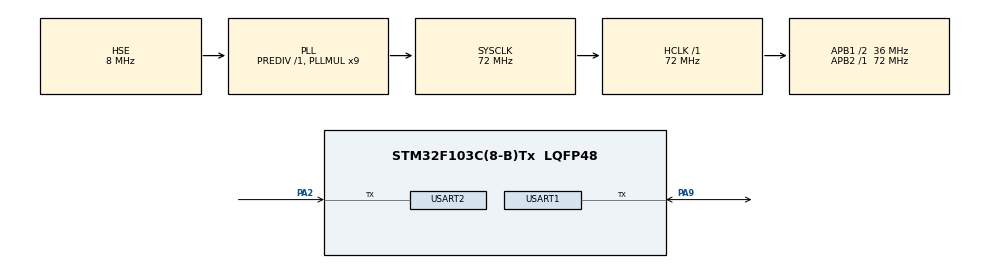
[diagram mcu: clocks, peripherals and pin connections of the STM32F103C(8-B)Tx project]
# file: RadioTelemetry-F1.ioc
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Dma.Request0=USART1_RX
Dma.Request1=USART1_TX
Dma.Request2=USART2_RX
Dma.USART1_RX.0.Direction=DMA_PERIPH_TO_MEMORY
Dma.USART1_RX.0.Instance=DMA1_Channel5
Dma.USART1_RX.0.MemDataAlignment=DMA_MDATAALIGN_BYTE
Dma.USART1_RX.0.MemInc=DMA_MINC_ENABLE
Dma.USART1_RX.0.Mode=DMA_NORMAL
Dma.USART1_RX.0.PeriphDataAlignment=DMA_PDATAALIGN_BYTE
Dma.USART1_RX.0.PeriphInc=DMA_PINC_DISABLE
Dma.USART1_RX.0.Priority=DMA_PRIORITY_LOW
Dma.USART1_TX.1.Direction=DMA_MEMORY_TO_PERIPH
Dma.USART1_TX.1.Instance=DMA1_Channel4
Dma.USART1_TX.1.MemDataAlignment=DMA_MDATAALIGN_BYTE
Dma.USART1_TX.1.MemInc=DMA_MINC_ENABLE
Dma.USART1_TX.1.Mode=DMA_NORMAL
Dma.USART1_TX.1.PeriphDataAlignment=DMA_PDATAALIGN_BYTE
Dma.USART1_TX.1.PeriphInc=DMA_PINC_DISABLE
Dma.USART1_TX.1.Priority=DMA_PRIORITY_LOW
Dma.USART2_RX.2.Direction=DMA_PERIPH_TO_MEMORY
Dma.USART2_RX.2.Instance=DMA1_Channel6
Dma.USART2_RX.2.MemDataAlignment=DMA_MDATAALIGN_BYTE
Dma.USART2_RX.2.MemInc=DMA_MINC_ENABLE
Dma.USART2_RX.2.Mode=DMA_NORMAL
Dma.USART2_RX.2.PeriphDataAlignment=DMA_PDATAALIGN_BYTE
Dma.USART2_RX.2.PeriphInc=DMA_PINC_DISABLE
Dma.USART2_RX.2.Priority=DMA_PRIORITY_LOW
Mcu.Family=STM32F1
Mcu.Name=STM32F103C(8-B)Tx
Mcu.Package=LQFP48
NVIC.DMA1_Channel4_IRQn=true\:0\:0\:false\:false\:true\:false\:true\:true
NVIC.DMA1_Channel5_IRQn=true\:0\:0\:false\:false\:true\:false\:true\:true
NVIC.DMA1_Channel6_IRQn=true\:0\:0\:false\:false\:true\:false\:true\:true
NVIC.PriorityGroup=NVIC_PRIORITYGROUP_4
NVIC.USART1_IRQn=true\:0\:0\:false\:false\:true\:true\:true\:true
PA13.Mode=Trace_Asynchronous_SW
PA13.Signal=SYS_JTMS-SWDIO
PA14.Mode=Trace_Asynchronous_SW
PA14.Signal=SYS_JTCK-SWCLK
PA2.Mode=Half_duplex(single_wire_mode)
PA2.Signal=USART2_TX
PA9.Mode=Half_duplex(single_wire_mode)
PA9.Signal=USART1_TX
PB3.Mode=Trace_Asynchronous_SW
PB3.Signal=SYS_JTDO-TRACESWO
PD0-OSC_IN.Mode=HSE-External-Oscillator
PD0-OSC_IN.Signal=RCC_OSC_IN
PD1-OSC_OUT.Mode=HSE-External-Oscillator
PD1-OSC_OUT.Signal=RCC_OSC_OUT
ProjectManager.HeapSize=0x200
ProjectManager.StackSize=0x400
ProjectManager.TargetToolchain=STM32CubeIDE
RCC.AHBFreq_Value=72000000
RCC.APB1CLKDivider=RCC_HCLK_DIV2
RCC.APB1Freq_Value=36000000
RCC.APB1TimFreq_Value=72000000
RCC.APB2Freq_Value=72000000
RCC.APB2TimFreq_Value=72000000
RCC.HCLKFreq_Value=72000000
RCC.PLLMUL=RCC_PLL_MUL9
RCC.PLLSourceVirtual=RCC_PLLSOURCE_HSE
RCC.SYSCLKFreq_VALUE=72000000
RCC.SYSCLKSource=RCC_SYSCLKSOURCE_PLLCLK
RCC.USBFreq_Value=72000000
USART1.VirtualMode=VM_ASYNC
USART2.Mode=MODE_RX
USART2.VirtualMode=VM_ASYNC
board=custom

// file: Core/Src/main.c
/* USER CODE BEGIN Header */
/**
  ******************************************************************************
  * @file           : main.c
  * @brief          : Main program body
  ******************************************************************************
  * @attention
  *
  * Copyright (c) 2022 STMicroelectronics.
  * All rights reserved.
  *
  * This software is licensed under terms that can be found in the LICENSE file
  * in the root directory of this software component.
  * If no LICENSE file comes with this software, it is provided AS-IS.
  *
  ******************************************************************************
  */
/* USER CODE END Header */
#include "main.h"
#include "dma.h"
#include "usart.h"
#include "gpio.h"

/* USER CODE BEGIN Includes */
#include <Telemetry.h>

/* USER CODE END Includes */

/* USER CODE BEGIN PV */
TelemetrySensorStruct SensorList[NUM_SENSORS] = {
		{0x01, 623},   	// IBUS_SENSOR_TYPE_TEMPERATURE
		{0x03, 1170},	// IBUS_SENSOR_TYPE_EXTERNAL_VOLTAGE
		{0x08, 57}, 	// IBUS_SENSOR_TYPE_CMP_HEAD
		{0x0B, 0x0100}, // IBUS_SENSOR_TYPE_GPS_STATUS

		{0x0C, 140}, 	// IBUS_SENSOR_TYPE_ACC_X
		{0x0D, 150}, 	// IBUS_SENSOR_TYPE_ACC_Y
		{0x0E, 160}, 	// IBUS_SENSOR_TYPE_ACC_Z
		{0x0F, 170}, 	// IBUS_SENSOR_TYPE_ROLL
		{0x10, 180}, 	// IBUS_SENSOR_TYPE_PITCH
		{0x11, 190}, 	// IBUS_SENSOR_TYPE_YAW

		{0x16, 1},		// IBUS_SENSOR_TYPE_FLIGHT_MODE
		{0x7E, 502},	// IBUS_SENSOR_TYPE_SPE
		{0x82, 21520},	// AFHDS2A_ID_GPS_ALT
		{0x83, 21520}	// AFHDS2A_ID_ALT
		// {},
	};
/* USER CODE END PV */

void SystemClock_Config(void);

int main(void)
{

  /* MCU Configuration--------------------------------------------------------*/

  /* Reset of all peripherals, Initializes the Flash interface and the Systick. */
  HAL_Init();

  /* Configure the system clock */
  SystemClock_Config();

  /* Initialize all configured peripherals */
  MX_GPIO_Init();
  MX_DMA_Init();
  MX_USART1_UART_Init();
  MX_USART2_UART_Init();
  /* USER CODE BEGIN 2 */
  Sensor_UART_Telemetry_Init(&huart1);
  Servo_UART_Telemetry_Init(&huart2);

  /* USER CODE END 2 */

  /* Infinite loop */
  while (1)
  {

    /* USER CODE BEGIN 3 */
	  printf("%ld: ", HAL_GetTick());
	  for(uint8_t i = 1; i <= NUM_SENSORS; i++)
		  printf("%d\t", (uint16_t) *(((uint16_t*) &ServoList)+i) );
	  printf("\t%d\n", sizeof(FLAGS));

	  HAL_Delay(1000);
  }
  /* USER CODE END 3 */
}

void SystemClock_Config(void)
{
  RCC_OscInitTypeDef RCC_OscInitStruct = {0};
  RCC_ClkInitTypeDef RCC_ClkInitStruct = {0};

  /** Initializes the RCC Oscillators according to the specified parameters
  * in the RCC_OscInitTypeDef structure.
  */
  RCC_OscInitStruct.OscillatorType = RCC_OSCILLATORTYPE_HSE;
  RCC_OscInitStruct.HSEState = RCC_HSE_ON;
  RCC_OscInitStruct.HSEPredivValue = RCC_HSE_PREDIV_DIV1;
  RCC_OscInitStruct.HSIState = RCC_HSI_ON;
  RCC_OscInitStruct.PLL.PLLState = RCC_PLL_ON;
  RCC_OscInitStruct.PLL.PLLSource = RCC_PLLSOURCE_HSE;
  RCC_OscInitStruct.PLL.PLLMUL = RCC_PLL_MUL9;
  if (HAL_RCC_OscConfig(&RCC_OscInitStruct) != HAL_OK)
  {
    Error_Handler();
  }

  /** Initializes the CPU, AHB and APB buses clocks
  */
  RCC_ClkInitStruct.ClockType = RCC_CLOCKTYPE_HCLK|RCC_CLOCKTYPE_SYSCLK
                              |RCC_CLOCKTYPE_PCLK1|RCC_CLOCKTYPE_PCLK2;
  RCC_ClkInitStruct.SYSCLKSource = RCC_SYSCLKSOURCE_PLLCLK;
  RCC_ClkInitStruct.AHBCLKDivider = RCC_SYSCLK_DIV1;
  RCC_ClkInitStruct.APB1CLKDivider = RCC_HCLK_DIV2;
  RCC_ClkInitStruct.APB2CLKDivider = RCC_HCLK_DIV1;

  if (HAL_RCC_ClockConfig(&RCC_ClkInitStruct, FLASH_LATENCY_2) != HAL_OK)
  {
    Error_Handler();
  }
}

/* USER CODE BEGIN 4 */

// ITM SWO Printf Implementation
int __io_putchar(int ch)
{
	ITM_SendChar(ch);
	return(ch);
}

/* USER CODE END 4 */

void Error_Handler(void)
{
  __disable_irq();
  while (1)
  {
  }
}
